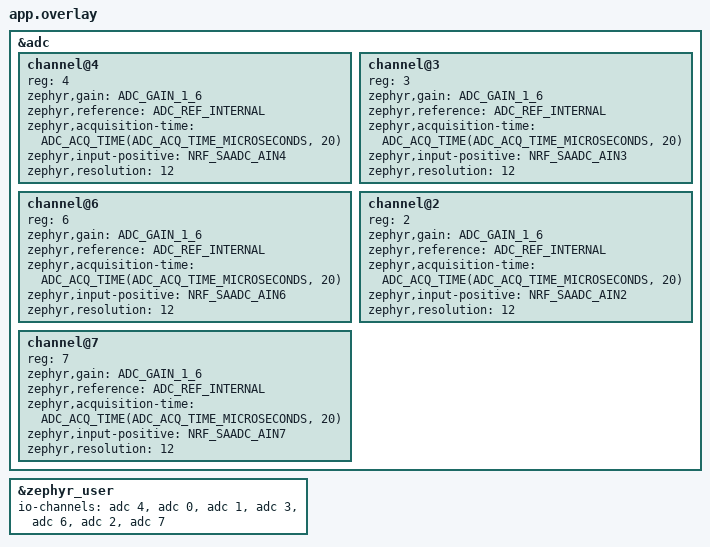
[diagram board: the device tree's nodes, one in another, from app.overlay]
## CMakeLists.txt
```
cmake_minimum_required(VERSION 3.20.0)
find_package(Zephyr REQUIRED HINTS $ENV{ZEPHYR_BASE})
project(wakes-sp1)

# Pulls in the samples' usbd bring-up helper (sample_usbd_init_device) and its
# CONFIG_SAMPLE_USBD_* options. Same approach as sp1-tape-looper. If this path is
# unavailable on your Zephyr, see docs/BUILD.md -> "USB console fallback".
include(${ZEPHYR_BASE}/samples/subsys/usb/common/common.cmake)

# ---- the engine list: generated from docs/PLAITS-ENGINES.md (M3b) ----
# The markdown table is the source of truth for engine order, LED patterns, enabled
# engines and centre detents. Edit it and rebuild; the build fails with a clear message
# if the table is malformed or a row's LED pattern does not match its position.
set(SP1_ENGINES_MD  ${CMAKE_CURRENT_SOURCE_DIR}/../docs/PLAITS-ENGINES.md)
set(SP1_ENGINES_GEN ${CMAKE_CURRENT_SOURCE_DIR}/../tools/gen_engines.py)
set(SP1_ENGINES_H   ${CMAKE_CURRENT_BINARY_DIR}/sp1_generated/sp1_engines_gen.h)
add_custom_command(
	OUTPUT  ${SP1_ENGINES_H}
	COMMAND ${Python3_EXECUTABLE} ${SP1_ENGINES_GEN} ${SP1_ENGINES_MD} ${SP1_ENGINES_H}
	DEPENDS ${SP1_ENGINES_MD} ${SP1_ENGINES_GEN}
	COMMENT "Generating the engine table from docs/PLAITS-ENGINES.md"
)
add_custom_target(sp1_engines_gen DEPENDS ${SP1_ENGINES_H})
add_dependencies(app sp1_engines_gen)
target_include_directories(app PRIVATE ${CMAKE_CURRENT_BINARY_DIR}/sp1_generated)

target_sources(app PRIVATE
	src/main.c
	src/sp1_led.c
	src/sp1_power.c
	src/sp1_batt.c
	src/sp1_standby.c
	src/sp1_console.c
	src/sp1_controls.c
	src/sp1_display.c
	src/sp1_calib.c
	src/sp1_audio.c
	src/sp1_meter.c
	src/sp1_playrow.c
	src/sp1_plaits_ui.c
)

# ---- M3: the Plaits voice (third_party/eurorack, vendored unmodified) ----
# Built as its own Zephyr library so it gets its OWN optimisation flags. The rest of
# the firmware is built -Os (CONFIG_SIZE_OPTIMIZATIONS); the DSP is the one place where
# cycles matter more than bytes, and the audio budget was measured assuming Plaits' own
# build: -O2 -funroll-loops, as in stmlib/makefile.inc for the Cortex-M4. Options added
# here come after the global ones on the command line, so this -O2 wins.
if(CONFIG_SP1_PLAITS)
	set(ER ${CMAKE_CURRENT_SOURCE_DIR}/../third_party/eurorack)

	zephyr_library_named(sp1_plaits)

	# ---- Plaits overrides: trims without modifying the vendored code ----
	# Two kinds, both leave third_party/ untouched:
	#
	# sp1_plaits_override(<file under third_party/eurorack> <exact upstream text>
	#                     <replacement>)                                   (M3e)
	#   Writes a copy of the file with ONE passage replaced into the build directory.
	#   A header copy shadows upstream's through the include path (searched first);
	#   a .cc copy is compiled INSTEAD of upstream's. The build stops if the upstream
	#   text is not found exactly once, so an upstream change can never silently
	#   disable a trim. At most one override per file.
	#
	# sp1_plaits_replace(<file under third_party/eurorack>)                (M3f)
	#   Our own rewrite of a whole file, kept at src/plaits_ovr/<same path> (attributed
	#   to upstream in its header and in NOTICE). Headers there shadow upstream's; a
	#   .cc there is compiled instead of upstream's.
	#
	# Each trim has a static_assert in sp1_synth.cc proving what was compiled.
	set(SP1_OVR ${CMAKE_CURRENT_BINARY_DIR}/plaits_overrides)
	set(SP1_REPL ${CMAKE_CURRENT_SOURCE_DIR}/src/plaits_ovr)
	set_property(GLOBAL PROPERTY SP1_PLAITS_SWAP "")
	function(sp1_plaits_swap rel ours)
		get_property(swaps GLOBAL PROPERTY SP1_PLAITS_SWAP)
		if("${rel}" IN_LIST swaps)
			message(FATAL_ERROR "Plaits override: ${rel} is overridden twice")
		endif()
		set_property(GLOBAL APPEND PROPERTY SP1_PLAITS_SWAP ${rel})
		set_property(GLOBAL PROPERTY SP1_PLAITS_SWAP_TO_${rel} ${ours})
	endfunction()
	function(sp1_plaits_override rel from to)
		set(src ${ER}/${rel})
		file(READ ${src} text)
		string(REPLACE "${from}" "" stripped "${text}")
		string(LENGTH "${text}" n0)
		string(LENGTH "${stripped}" n1)
		string(LENGTH "${from}" nf)
		math(EXPR count "(${n0} - ${n1}) / ${nf}")
		if(NOT count EQUAL 1)
			message(FATAL_ERROR
				"Plaits override: expected '${from}' exactly once in ${rel}, "
				"found ${count}. Upstream changed? Re-check the trim.")
		endif()
		if(EXISTS ${SP1_REPL}/${rel})
			message(FATAL_ERROR "Plaits override: ${rel} is also replaced in src/plaits_ovr")
		endif()
		string(REPLACE "${from}" "${to}" text "${text}")
		set(text "// GENERATED by firmware/CMakeLists.txt (sp1_plaits_override) from\n// third_party/eurorack/${rel}. Do not edit; see the override in CMakeLists.txt.\n${text}")
		# Write via configure_file so the copy's timestamp only changes when its
		# content does (no needless full Plaits rebuild on every reconfigure).
		file(WRITE ${SP1_OVR}/${rel}.tmp "${text}")
		configure_file(${SP1_OVR}/${rel}.tmp ${SP1_OVR}/${rel} COPYONLY)
		set_property(DIRECTORY APPEND PROPERTY CMAKE_CONFIGURE_DEPENDS ${src})
		if(rel MATCHES "\\.cc$")
			sp1_plaits_swap(${rel} ${SP1_OVR}/${rel})
		else()
			sp1_plaits_swap(${rel} "")
		endif()
	endfunction()
	function(sp1_plaits_replace rel)
		if(NOT EXISTS ${SP1_REPL}/${rel})
			message(FATAL_ERROR "Plaits replace: src/plaits_ovr/${rel} not found")
		endif()
		if(rel MATCHES "\\.cc$")
			sp1_plaits_swap(${rel} ${SP1_REPL}/${rel})
		else()
			sp1_plaits_swap(${rel} "")
		endif()
	endfunction()

	# M3e: String rings CONFIG_SP1_STRING_VOICES strings (upstream 3).
	sp1_plaits_override(plaits/dsp/engine/string_engine.h
		"const int kNumStrings = 3;"
		"const int kNumStrings = ${CONFIG_SP1_STRING_VOICES};")
	# M3f: Particle: CONFIG_SP1_PARTICLES particles (upstream 6). Plaits divides the
	# density by the count, so the event rate is unchanged.
	sp1_plaits_override(plaits/dsp/engine/particle_engine.h
		"const int kNumParticles = 6;"
		"const int kNumParticles = ${CONFIG_SP1_PARTICLES};")
	# M3f: Particle: skip the diffuser while MORPH >= centre, where Plaits mixes it in
	# at exactly 0 (diffusion = 0). Cleared when it comes back into use, so no stale
	# tail from the last time it ran is heard.
	sp1_plaits_override(plaits/dsp/engine/particle_engine.cc
		"  diffuser_.Process("
		"  // wakes-sp1 (M3f): the diffuser's mix amount is exactly 0 when diffusion is 0.\n  static bool sp1_diffusing = false;\n  if (diffusion > 0.0f && !sp1_diffusing) {\n    diffuser_.Reset();\n  }\n  sp1_diffusing = diffusion > 0.0f;\n  if (sp1_diffusing) diffuser_.Process(")
	# M3f: Modal: CONFIG_SP1_MODAL_MODES resonator modes (upstream 24). Resonator is
	# used by the modal engine only.
	sp1_plaits_override(plaits/dsp/physical_modelling/resonator.h
		"const int kMaxNumModes = 24;"
		"const int kMaxNumModes = ${CONFIG_SP1_MODAL_MODES};")
	# M3f: Additive: our rewrite of the partial summation (same 24 + 8 partials).
	sp1_plaits_replace(plaits/dsp/engine/additive_engine.h)
	sp1_plaits_replace(plaits/dsp/engine/additive_engine.cc)
	# M3g: String machine: the ensemble skips its taps while its amount is exactly 0
	# (TIMBRE on the centre detent); the divide-down oscillator (also used by Chords)
	# holds its gains per block. Both headers only.
	sp1_plaits_replace(plaits/dsp/fx/ensemble.h)
	sp1_plaits_replace(plaits/dsp/oscillator/string_synth_oscillator.h)
	# ---- M4a: a HARMONICS attenuverter (Adara) ----
	# Plaits' panel has attenuverters on FM, TIMBRE and MORPH but not on HARMONICS: its
	# HARMONICS CV is summed in raw, and -- the part that matters musically -- HARMONICS
	# is the one parameter the internal decay envelope can never reach, because that
	# routing is what an unpatched attenuverter means on the other three.
	#
	# These two overrides give HARMONICS the same treatment, which is a genuine addition
	# to Plaits rather than a re-binding. Together they add `harmonics_modulation_amount`
	# to Patch and `harmonics_patched` to Modulations, then run HARMONICS through the
	# same ApplyModulations() as the other three. The envelope amount is the plain
	# decay envelope, like TIMBRE's: the speech engine's `internal_envelope_amplitude`
	# is computed FROM p.harmonics, so using it here would be circular.
	#
	# ⚠️ Patch and Modulations are laid out by this header for EVERY Plaits file, so the
	# override must shadow upstream for all of them -- that is what SP1_OVR being first
	# on the include path does. sp1_synth.cc static_asserts that it took.
	# One passage, because a file may only be overridden once and the two new fields
	# live in two different structs.
	sp1_plaits_override(plaits/dsp/voice.h
		"  float morph_modulation_amount;

  int engine;
  float decay;
  float lpg_colour;
};

struct Modulations {
  float engine;
  float note;
  float frequency;
  float harmonics;
  float timbre;
  float morph;
  float trigger;
  float level;

  bool frequency_patched;"
		"  float morph_modulation_amount;
  // wakes-sp1 (M4a): HARMONICS gets an attenuverter of its own. Upstream has none.
  float harmonics_modulation_amount;

  int engine;
  float decay;
  float lpg_colour;

  // Proof to sp1_synth.cc's static_assert that this override was compiled.
  static const bool kSp1HarmonicsAttenuverter = true;
};

struct Modulations {
  float engine;
  float note;
  float frequency;
  float harmonics;
  float timbre;
  float morph;
  float trigger;
  float level;

  bool harmonics_patched;   // wakes-sp1 (M4a)
  bool frequency_patched;")
	sp1_plaits_override(plaits/dsp/voice.cc
		"  p.harmonics = patch.harmonics + modulations.harmonics;
  CONSTRAIN(p.harmonics, 0.0f, 1.0f);"
		"  // wakes-sp1 (M4a): HARMONICS through the same attenuverter + internal-envelope
  // path as TIMBRE and MORPH. Upstream is: p.harmonics = patch.harmonics +
  // modulations.harmonics, constrained to 0..1.
  p.harmonics = ApplyModulations(
      patch.harmonics,
      patch.harmonics_modulation_amount,
      modulations.harmonics_patched,
      modulations.harmonics,
      use_internal_envelope,
      decay_envelope_.value(),
      0.0f,
      0.0f,
      1.0f);")
	# ---- M4c: the X / Y voltage range becomes PER CHANNEL ----
	# Marbles' range is a per-GROUP setting and XYGenerator::Process writes it into each
	# channel's ScaleOffset itself, every block -- so anything we set per channel would be
	# overwritten. This makes that one switch ask us which range channel `i` should get.
	#
	# All the policy lives in sp1_marbles.cc (IntelligentRange); this override holds none,
	# and a non-INTELLIGENT group still gets exactly what upstream gave it. The local
	# extern declaration keeps it to a single replaced passage, which is the limit of one
	# override per file.
	sp1_plaits_override(marbles/random/x_y_generator.cc
		"    switch (settings.voltage_range) {"
		"    // wakes-sp1 (M4c): the range is per CHANNEL, not per group.
    // A block-scope extern declares the name in the innermost enclosing NAMESPACE, so
    // this is marbles::sp1_mrb_channel_range -- defined in firmware/src/sp1_marbles.cc.
    // (`extern \"C\"` is not allowed at block scope, hence C++ linkage.)
    extern int sp1_mrb_channel_range(int channel, int group_range);
    switch (static_cast<VoltageRange>(sp1_mrb_channel_range(
        static_cast<int>(i), static_cast<int>(settings.voltage_range)))) {")
	# M4: Marbles' t generator gets a setter for its master phase, so PLAY starts the
	# clock on a beat (sp1_marbles.cc). Nothing else in Marbles is changed.
	sp1_plaits_override(marbles/random/t_generator.h
		"  inline void set_model(TGeneratorModel model) {"
		"  // wakes-sp1 (M4): PLAY starts the clock on a beat.\n  inline void set_master_phase(float phase) {\n    master_phase_ = phase;\n  }\n\n  inline void set_model(TGeneratorModel model) {")

	set(PLAITS_SOURCES
		${ER}/plaits/dsp/voice.cc
		${ER}/plaits/resources.cc
		${ER}/stmlib/dsp/atan.cc
		${ER}/stmlib/dsp/units.cc
		${ER}/stmlib/utils/random.cc
	)
	file(GLOB PLAITS_ENGINE_SOURCES
		${ER}/plaits/dsp/engine/*.cc
		${ER}/plaits/dsp/engine2/*.cc
		${ER}/plaits/dsp/chords/*.cc
		${ER}/plaits/dsp/fm/*.cc
		${ER}/plaits/dsp/physical_modelling/*.cc
		${ER}/plaits/dsp/speech/*.cc
	)
	list(APPEND PLAITS_SOURCES ${PLAITS_ENGINE_SOURCES})
	# M4: Marbles' generators (third_party/eurorack/README.md), same library and flags.
	file(GLOB MARBLES_SOURCES
		${ER}/marbles/random/*.cc
		${ER}/marbles/ramp/*.cc
	)
	list(APPEND PLAITS_SOURCES ${MARBLES_SOURCES} ${ER}/marbles/resources.cc)
	get_property(swaps GLOBAL PROPERTY SP1_PLAITS_SWAP)
	foreach(rel ${swaps})
		get_property(ours GLOBAL PROPERTY SP1_PLAITS_SWAP_TO_${rel})
		if(ours)
			list(FIND PLAITS_SOURCES ${ER}/${rel} idx)
			if(idx EQUAL -1)
				message(FATAL_ERROR "Plaits override: ${rel} is not a Plaits source")
			endif()
			list(REMOVE_AT PLAITS_SOURCES ${idx})
			list(APPEND PLAITS_SOURCES ${ours})
		endif()
	endforeach()
	zephyr_library_sources(src/sp1_synth.cc src/sp1_marbles.cc ${PLAITS_SOURCES})

	# ⚠️ ORDER MATTERS: generated overrides, our replacements, the shim, then the
	# eurorack root. The shim's plaits/user_data.h shadows upstream's (which reads an
	# STM32 flash address that is a bus fault on the nRF52840). See
	# src/plaits_shim/plaits/user_data.h.
	zephyr_library_include_directories(
		${SP1_OVR}
		${SP1_REPL}
		src/plaits_shim
		${ER}
	)
	zephyr_library_compile_options(
		# GNU dialect, as upstream's own build (strict -std=c++14 from CONFIG_STD_CPP14
		# otherwise), plus _DEFAULT_SOURCE: Zephyr's feature macros hide M_PI in
		# picolibc's <math.h>, and stmlib and Plaits use it throughout.
		$<$<COMPILE_LANGUAGE:CXX>:-std=gnu++14>
		-D_DEFAULT_SOURCE
		-O2
		-funroll-loops
		-finline-functions-called-once
		-fno-move-loop-invariants
		# Upstream code, compiled as-is: silence what it was never written against.
		-Wno-unused-variable
		-Wno-unused-parameter
		-Wno-unused-local-typedefs
		-Wno-sign-compare
		-Wno-double-promotion
	)
	# A Zephyr library declared from the APPLICATION is not linked on its own.
	target_link_libraries(app PRIVATE sp1_plaits)
	target_sources(app PRIVATE src/sp1_marbles_ui.c)
	target_include_directories(app PRIVATE src)
endif()
```

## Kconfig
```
# wakes-sp1 application Kconfig.
#
# Pulls in the common USB sample options (CONFIG_SAMPLE_USBD_VID/PID/PRODUCT/...)
# consumed by the vendored sample_usbd_init helper, then the standard Zephyr tree.
source "samples/subsys/usb/common/Kconfig.sample_usbd"

menu "wakes-sp1"

config SP1_PLAITS
	bool "Plaits voice as the audio source (M3)"
	default y
	select CPP
	help
	  y: PLAY triggers the Plaits voice (2-op FM), faders are FREQUENCY /
	  TIMBRE / MORPH / HARMONICS, VOL+/- set the output level.
	  n: the M2 440 Hz test tone instead, with its PLAY / VOL controls, and
	  none of the Plaits code is compiled or linked.

	  This is the FALLBACK SWITCH. If the voice faults or overruns on hardware,
	  set CONFIG_SP1_PLAITS=n in prj.conf and rebuild: everything else in the
	  build (headphone mute, LEDs, power) stays exactly as it was.

config SP1_STRING_VOICES
	int "String engine: number of strings (Plaits kNumStrings)"
	range 1 3
	default 2
	depends on SP1_PLAITS
	help
	  How many strings Plaits' String engine rings at once. Upstream is 3.
	  Each TRIG plucks the next string round-robin, so this is how many
	  notes can overlap before the oldest one is re-plucked.

	  2 (default, M3e): every string costs the same, so 2 saves a third of
	  the engine -- 598.6 -> 427.3 instructions/sample in tools/plaits-bench,
	  about 90 % -> 65 % of the audio budget on the SP-1. At 3, String
	  measured 90 % average and 98.5 % peak: it played, with no headroom.

	  Applied at build time to a generated copy of string_engine.h; the
	  vendored file is not modified (see "Plaits overrides" in
	  firmware/CMakeLists.txt). Set it to 3 in prj.conf to A/B the original.

config SP1_PARTICLES
	int "Particle engine: number of particles (Plaits kNumParticles)"
	range 1 6
	default 2
	depends on SP1_PLAITS
	help
	  How many resonant "particles" Plaits' Particle engine runs. Upstream
	  is 6. Plaits divides the density by this count, so the rate of events
	  is the same; fewer means fewer pings ringing at different pitches at
	  once.

	  2 (default, M3h): at 3 (M3f) the SP-1 peaked at 83-100 %, all of it
	  below MORPH centre where the diffuser runs (Adara). Each particle is
	  ~43 instructions/sample. At 6 (upstream) it measured 86 % average /
	  97 % peak. The diffuser is skipped above MORPH centre in any case.

config SP1_MODAL_MODES
	int "Modal engine: number of resonator modes (Plaits kMaxNumModes)"
	range 4 24
	default 12
	depends on SP1_PLAITS
	help
	  Partials of Plaits' modal resonator. Upstream is 24. Must be a
	  multiple of 4 (the resonator renders modes in batches of 4; the build
	  checks). Fewer modes drop the highest partials: the body of a bell
	  stays, its shimmer goes.

	  12 (default, M3g): 8 measured 49 % average / 54 % peak on the SP-1
	  and sounded band-limited (Adara); each batch of 4 modes costs ~100
	  instructions/sample, ~16 %, so 12 is expected near 65 % / 70 %.
	  8 is the fallback. 16 would be ~80 % average -- over the target.

endmenu

source "Kconfig.zephyr"
```

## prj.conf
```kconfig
# wakes-sp1 M0 — the safety floor.
#
# Deliberately minimal. No USB, no console, no audio, no ADC. Every option
# here either keeps the device recoverable or is required to boot at all.
# Things are ADDED in later milestones, never removed to fix a build.

# ---- Recoverability ----
# The watchdog is the final backstop for a hang on a device with no reset pin.
CONFIG_WATCHDOG=y
# k_sys_fatal_error_handler() in main.c turns any fault into a cold reboot.
CONFIG_REBOOT=y

# ---- Fault containment ----
# HW_STACK_PROTECTION reprograms the MPU stack guard on every context switch.
# sp1-tape-looper measured that at ~1 % at the corner and turned it off in
# favour of the cheaper STACK_SENTINEL canary (which Kconfig excludes while
# MPU_STACK_GUARD is on). M0 has CPU to spare and no audio deadline yet, so
# keep the stronger guard here and revisit at M2 when the deadline is real.
CONFIG_HW_STACK_PROTECTION=y

# ---- USB CDC ACM console (M1c) ----
# Exists to make two things possible that are miserable blind: calibrating the
# battery divider, and building the button-ladder threshold tables in M1d.
#
# device_next rather than the legacy CONFIG_USB_DEVICE_STACK: legacy is smaller but
# deprecated, mass storage later would need device_next anyway, and this is the path
# sp1-tape-looper proved on this board and this Zephyr version.
CONFIG_CONSOLE=y
CONFIG_PRINTK=y
CONFIG_SERIAL=y
CONFIG_UART_CONSOLE=y
CONFIG_UART_LINE_CTRL=y
CONFIG_UART_INTERRUPT_DRIVEN=y

CONFIG_USB_DEVICE_STACK_NEXT=y
CONFIG_USBD_CDC_ACM_CLASS=y
# The app owns the single USBD context; do not let the CDC SYS_INIT build a second
# private one that would fight for the controller.
CONFIG_CDC_ACM_SERIAL_INITIALIZE_AT_BOOT=n
CONFIG_HWINFO=y
CONFIG_SAMPLE_USBD_PID=0x5211
CONFIG_SAMPLE_USBD_MANUFACTURER="worldwave"
CONFIG_SAMPLE_USBD_PRODUCT="wakes-sp1"
# iOS rejects accessories claiming more than 100 mA over the camera adapter, and we
# run from our own battery. Units of 2 mA.
CONFIG_SAMPLE_USBD_MAX_POWER=50

CONFIG_LOG=n
CONFIG_ASSERT=n

# The USB stack's init and printf need more main stack than the bare power build.
# 3 KB from M3 (was 2 KB): main now uses the FPU (fader smoothing), so every exception
# taken on its stack carries the extended FP frame, and it calls printk with more args.
CONFIG_MAIN_STACK_SIZE=3072

# ---- Clocking ----
# Matches what the bootloader leaves behind. Do not change without reading
# docs/SAFETY.md -- re-initialising bootloader-owned clocks is on the "do not"
# list for this board.
CONFIG_CLOCK_CONTROL=y
CONFIG_CLOCK_CONTROL_NRF_K32SRC_SYNTH=y


# ---- LED rows on hardware PWM (M1a) ----
# Hardware PWM costs no CPU (EasyDMA), unlike the software PWM sp1-tape-looper
# uses -- which needed a zero-latency IRQ to stop flicker and would compete with
# the audio deadline from M2 on. Do not replace this with a software PWM.
CONFIG_PWM=y
CONFIG_PWM_NRFX=y

# ---- Battery voltage (M1b) ----
# SAADC on AIN4. Only the battery channel for now; the faders join in M1c.
CONFIG_ADC=y

# ---- Output naming ----
# Renames build/zephyr/zephyr.{elf,bin,hex,map,...} to wakes-sp1.{elf,bin,hex,map,...}.
# The build/zephyr/ subdirectory itself is unaffected -- that name comes from the
# Zephyr CMake target, not this option.
CONFIG_KERNEL_BIN_NAME="wakes-sp1"

# ---- Audio output (M2) ----
# I2C to the two codecs (CS42L42 headphone at 0x48, TAS2505 speaker amp at 0x18),
# and the I2S stream as a CLOCK SLAVE on both clocks -- see sp1_audio.h for the
# topology. Same three options sp1-tape-looper proved on this board.
CONFIG_I2C=y
CONFIG_I2S=y
CONFIG_I2S_NRFX=y

# Floating-point unit. Nothing in M2 uses float -- the tone and the meter are
# integer-only on purpose -- but Plaits is float throughout from M3. Turning the FPU
# on HERE means M3 changes one thing (the synth), not two (the synth and the
# FP context-switch behaviour).
CONFIG_FPU=y
# Preserve FP registers across context switches. CONFIG_FPU alone is Zephyr's
# UNSHARED mode: FP state is not saved when threads switch. Plaits (float) will run in
# the audio thread, and any float in main, USB or an ISR would silently corrupt it --
# and with the hard-float ABI the compiler may use VFP registers for plain data moves
# too. Set now, with the FPU, so M3 does not inherit a latent corruption bug.
CONFIG_FPU_SHARING=y

# ---- M3: the Plaits voice ----
# The fallback switch: n = the M2 test tone, and no Plaits code is built at all.
CONFIG_SP1_PLAITS=y
# Plaits is C++ (no exceptions, no RTTI -- the Zephyr defaults) and needs <algorithm>
# and <cmath>, which the minimal C++ library does not provide.
CONFIG_CPP=y
CONFIG_STD_CPP14=y
CONFIG_GLIBCXX_LIBCPP=y
# ⚠️ The audio thread runs at K_PRIO_PREEMPT(0) and MUST outrank main, so main moves
# to 1. From M3 the audio work is ~half the CPU; at equal priority the ADC scan and
# every printk would compete with the audio deadline. See sp1_audio.h.
CONFIG_MAIN_THREAD_PRIORITY=1
```

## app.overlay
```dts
/*
 * wakes-sp1 application overlay.
 *
 * M1d adds the four faders, APPENDED after the battery so it keeps io-channel
 * index 0 and sp1_batt.c never has to be renumbered.
 *
 * `reg` is chosen to equal the AIN number for the faders, which makes the mapping
 * readable against the schematic. The io-channel INDEX is what C uses, and the two
 * are deliberately different things -- see sp1_controls.c.
 *
 * Gain 1/6 + ADC_REF_INTERNAL matches the ladder channels in the board DTS, and
 * that pairing is load-bearing: published millivolt threshold tables are only
 * valid under the ADC configuration they were measured in. sp1-midi uses gain 1/4
 * with VDD/4 -- never mix the two.
 */

#include <zephyr/dt-bindings/adc/adc.h>
#include <zephyr/dt-bindings/adc/nrf-saadc.h>

&adc {
	/* Battery voltage, P0.28 / AIN4, via an on-board divider of UNKNOWN ratio.
	 * See sp1_batt.h for how to calibrate it without opening the device. */
	channel@4 {
		reg = <4>;
		zephyr,gain = "ADC_GAIN_1_6";
		zephyr,reference = "ADC_REF_INTERNAL";
		zephyr,acquisition-time = <ADC_ACQ_TIME(ADC_ACQ_TIME_MICROSECONDS, 20)>;
		zephyr,input-positive = <NRF_SAADC_AIN4>;
		zephyr,resolution = <12>;
	};
};

&adc {
	/* Fader 1, P0.05 / AIN3 */
	channel@3 {
		reg = <3>;
		zephyr,gain = "ADC_GAIN_1_6";
		zephyr,reference = "ADC_REF_INTERNAL";
		zephyr,acquisition-time = <ADC_ACQ_TIME(ADC_ACQ_TIME_MICROSECONDS, 20)>;
		zephyr,input-positive = <NRF_SAADC_AIN3>;
		zephyr,resolution = <12>;
	};
	/* Fader 2, P0.30 / AIN6 */
	channel@6 {
		reg = <6>;
		zephyr,gain = "ADC_GAIN_1_6";
		zephyr,reference = "ADC_REF_INTERNAL";
		zephyr,acquisition-time = <ADC_ACQ_TIME(ADC_ACQ_TIME_MICROSECONDS, 20)>;
		zephyr,input-positive = <NRF_SAADC_AIN6>;
		zephyr,resolution = <12>;
	};
	/* Fader 3, P0.04 / AIN2 */
	channel@2 {
		reg = <2>;
		zephyr,gain = "ADC_GAIN_1_6";
		zephyr,reference = "ADC_REF_INTERNAL";
		zephyr,acquisition-time = <ADC_ACQ_TIME(ADC_ACQ_TIME_MICROSECONDS, 20)>;
		zephyr,input-positive = <NRF_SAADC_AIN2>;
		zephyr,resolution = <12>;
	};
	/* Fader 4, P0.31 / AIN7 */
	channel@7 {
		reg = <7>;
		zephyr,gain = "ADC_GAIN_1_6";
		zephyr,reference = "ADC_REF_INTERNAL";
		zephyr,acquisition-time = <ADC_ACQ_TIME(ADC_ACQ_TIME_MICROSECONDS, 20)>;
		zephyr,input-positive = <NRF_SAADC_AIN7>;
		zephyr,resolution = <12>;
	};
};

&zephyr_user {
	/* ORDER IS THE C-VISIBLE INDEX. Battery must stay index 0.
	 *   0 battery   1 ladder-tracks   2 ladder-vol
	 *   3 fader1    4 fader2          5 fader3       6 fader4
	 * See the IO_* defines in sp1_controls.c -- they must match this order. */
	io-channels = <&adc 4>,
		      <&adc 0>, <&adc 1>,
		      <&adc 3>, <&adc 6>, <&adc 2>, <&adc 7>;
};
```

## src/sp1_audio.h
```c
/*
 * wakes-sp1 — audio output: codecs, 48 kHz I2S, output level, headphone detect, and
 * the block loop that runs the synth voice (M3) or the fallback test tone.
 *
 * ---- clock topology (TE's own, and the only one proven on this board) ----
 * The 3.072 MHz oscillator (P0.13) drives the I2S bit clock. The CS42L42 headphone
 * codec is the FRAME master: it divides that clock by 64 to make a frame clock of
 * exactly 48 000 Hz. The nRF52840 I2S peripheral and the TAS2505 speaker amp are both
 * CLOCK SLAVES. sp1-tape-looper found the hard way that having the nRF master the
 * clocks instead (at ~47 619 Hz) crackled on the speaker and gave only noise on the
 * headphones.
 *
 * ---- bring-up order, copied exactly from the proven path. DO NOT "TIDY" IT ----
 *   1. release both codec resets, 20 ms
 *   2. oscillator ON, 5 ms          -> the bit clock now exists
 *   3. start the I2S stream         -> nRF waits as a slave; there is no frame yet
 *   4. configure the TAS2505        -> its PLL locks to the BIT clock, already live
 *   5. configure the CS42L42        -> it starts mastering the FRAME clock, and the
 *                                      stream the nRF queued in step 3 begins to flow
 * Step 3 before step 5 looks backwards and is not: the amp only needs the bit clock,
 * the nRF just waits for frames, and this is the order that works on hardware.
 *
 * ---- priority: audio OUTRANKS main (M3) ----
 * Audio runs at K_PRIO_PREEMPT(0); CONFIG_MAIN_THREAD_PRIORITY=1 in prj.conf puts the
 * main loop below it. In M2 both were 0 and time-sliced (TIMESLICE_PRIORITY=0, 20 ms
 * slices), which was fine for a sine at ~7 % of the CPU and not for Plaits at ~50 %:
 * a 430 us ADC scan or a printk stalled by the host could then sit in front of an
 * audio block. Now the audio thread takes the CPU whenever a block is due, and main
 * runs in the gaps.
 *
 * ---- and therefore the audio thread must NEVER spin ----
 * The main loop is what feeds the watchdog and runs power-off. A thread that spins
 * ABOVE it starves both.
 *
 * What an OVERRUN does (voice slower than real time) -- checked against the pinned
 * i2s_nrfx.c, and not what an earlier version of this comment claimed: the driver
 * misses a buffer ("next buffers not supplied"), the stream goes to I2S_STATE_ERROR,
 * i2s_write() then fails at once, and the write-failure path SLEEPS 2 ms per failure
 * and re-primes after 8. So main still gets time: the device stays up with broken,
 * stuttering audio and a slower control loop, and power-off keeps working. It does
 * NOT starve into a watchdog reset -- so when debugging an overrun in M4, look for
 * `fail`/`rst` climbing on the AUD line, not for a reboot. CONFIG_SP1_PLAITS=n builds
 * the known-good tone firmware.
 *
 * tape-looper's write-failure path does `free; continue` with no sleep, which spins if
 * writes fail instantly. Every path through this thread blocks or sleeps instead. See
 * sp1_audio.c.
 *
 * ---- start/stop are bounded, always ----
 * sp1_audio_stop() is on the POWER-OFF path (sp1_quiesce_peripherals calls it). It
 * never waits more than 50 ms for the thread, whatever state the thread is in, and
 * power-off proceeds regardless -- rule 5a: power-off does not depend on anything
 * else succeeding.
 */
#ifndef SP1_AUDIO_H
#define SP1_AUDIO_H

#include <stdint.h>
#include <stdbool.h>

/* Create the audio thread (it parks immediately) and enable the DWT cycle counter.
 * Once, at boot, after the power-on gate. Safe to call stop() before this. */
void sp1_audio_init(void);

/* Bring the audio path up: resets released, oscillator on, stream started, both
 * codecs configured. Call on every entry to ON -- the way into STANDBY powers all of
 * it down. Bounded: never blocks longer than ~1 s, feeds the watchdog while it waits.
 * Returns 0 on success, negative if the stream could not be started. */
int sp1_audio_start(void);

/* Stop the stream. On the power-off path: waits at most 50 ms for the thread, then
 * returns REGARDLESS. Safe to call when audio was never started. */
void sp1_audio_stop(void);

/* Halt the I2S peripheral at register level and disconnect its pins. ONLY on the way
 * to SYSTEM_OFF -- never STANDBY, because the driver applies its pinctrl once at boot
 * and would not restore the pins. See sp1_audio.c. */
void sp1_audio_halt_for_system_off(void);

/* Peak |sample| (0..32767) of everything produced since the last call, then reset.
 * For the meter. Lock-free: one atomic swap. */
uint32_t sp1_audio_take_peak(void);

/* ---- OUTPUT LEVEL (VOL+ / VOL-) ----
 * 3 dB steps, slewed in the audio path so a change never clicks. Step 0 = 0 dBFS; the
 * last step is mute. Every TWO steps is one meter band (6.02 dB). Applies to the synth
 * and to the fallback tone alike, and to speaker and headphones alike -- the speaker's
 * extra speaker trim is separate and fixed (SP1_SPK_ATTEN_HALF_DB in sp1_audio.c:
 * -9 dB in M3, -6 dB since M4a). */
#define SP1_LEVEL_STEPS     12      /* 0 .. 10 = 0 .. -30 dB, 11 = mute */
#if defined(CONFIG_SP1_PLAITS)
#define SP1_LEVEL_DEFAULT    2      /* -6 dBFS                                */
#else
#define SP1_LEVEL_DEFAULT    4      /* -12 dBFS for the test tone, as in M2   */
#endif

void sp1_audio_level_step(int delta);  /* +1 = quieter by 3 dB, -1 = louder */
int  sp1_audio_level_get(void);
int  sp1_audio_level_db_x10(void);     /* tenths of dBFS, -9990 = mute      */

/* ---- the fallback test tone (CONFIG_SP1_PLAITS=n only): 440 Hz, off at start ---- */
void sp1_audio_tone_set(bool on);
bool sp1_audio_tone_on(void);

/* ---- headphone detect -> speaker mute (M3) ----
 * Call from the main loop every tick while ON, after sp1_audio_start(). Polls the
 * CS42L42 jack sense every 40 ms, debounced, and powers the speaker down while a plug
 * is in. Returns -1 (nothing new), 0 (unplugged: speaker on), 1 (plugged: speaker
 * off), or 2 (detect failed repeatedly: disabled for this session, speaker ON). */
int sp1_audio_jack_poll(uint32_t elapsed_ms);
int sp1_audio_jack_state(void);        /* 1 in, 0 out, -1 unknown */

/* Block cost since the last call: worst and mean cycles per block. Read-and-clear. */
void sp1_audio_take_cycles(uint32_t *max, uint32_t *avg);

/* ---- diagnostics ---- */
struct sp1_audio_stats {
	uint32_t blocks;         /* blocks handed to I2S                         */
	uint32_t write_fails;    /* i2s_write errors                             */
	uint32_t restarts;       /* stream drop + re-prime after repeated fails  */
	uint32_t cyc_max;        /* worst cycles spent generating one block      */
	uint32_t cyc_budget;     /* cycles available per block                   */
	int      cfg_rc;         /* last i2s_configure() result                  */
	bool     running;
	bool     tas_ok;         /* every TAS2505 write ACKed                    */
	bool     hp_ok;          /* CS42L42 identified and configured            */
};
void sp1_audio_stats(struct sp1_audio_stats *out);

#endif /* SP1_AUDIO_H */
```

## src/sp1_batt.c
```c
/* wakes-sp1 — battery voltage and charge estimate. See sp1_batt.h. */
#include "sp1_batt.h"

#include <zephyr/kernel.h>
#include <zephyr/device.h>
#include <zephyr/devicetree.h>
#include <zephyr/drivers/adc.h>

/* The battery is io-channel index 0 on zephyr_user. Faders APPEND after it when
 * they arrive, so this index never has to move. */
#define BATT_IO_IDX 0

static const struct adc_dt_spec batt_spec =
	ADC_DT_SPEC_GET_BY_IDX(DT_PATH(zephyr_user), BATT_IO_IDX);

/* Full scale: gain 1/6 with the 0.6 V internal reference => 3.6 V across 12 bits.
 * These MUST match the channel properties in firmware/app.overlay. */
#define ADC_FULL_SCALE_MV  3600u
#define ADC_MAX_COUNTS     4095u

/* SP1_BATT_DIVIDER_MILLI lives in sp1_batt.h so the console can report what we
 * are currently assuming alongside what it measured. A /2 divider is the likely
 * design: it puts a 4.20 V cell at 2.10 V, well inside the 3.6 V window. */

static uint16_t raw_last;
static uint16_t mv_last;
static bool     have_sample;
static bool     adc_ok;

/* Smoothed millivolts for display. Raw readings scatter +/-8 counts (~15 mV at the
 * cell), which made the computed level jitter between 247 and 255 -- visible as the
 * top LED of the charge bar wobbling. Hardware oversampling below takes most of it
 * out; this takes the rest. */
static uint32_t mv_smooth_q4;      /* millivolts, Q4 fixed point */
#define SMOOTH_SHIFT 3             /* first-order IIR, ~8-sample time constant */

int sp1_batt_init(void)
{
	if (!adc_is_ready_dt(&batt_spec)) {
		return -1;
	}
	if (adc_channel_setup_dt(&batt_spec) < 0) {
		return -1;
	}
	adc_ok = true;
	return 0;
}

void sp1_batt_sample(void)
{
	if (!adc_ok) {
		return;
	}

	int16_t buf = 0;
	struct adc_sequence seq = {
		.buffer      = &buf,
		.buffer_size = sizeof(buf),
	};
	if (adc_sequence_init_dt(&batt_spec, &seq) < 0) {
		return;
	}
	/* Hardware oversampling: the SAADC averages 2^n conversions for us, which is
	 * free compared with doing it in software.
	 *
	 * ⚠️ M1d NOTE: nrfx cannot oversample a sequence containing MORE THAN ONE
	 * channel. When the faders arrive, keep the battery in its own single-channel
	 * sequence rather than folding it into a scan, or this silently stops working. */
	seq.oversampling = 4;      /* 2^4 = 16 conversions averaged */
	if (adc_read(batt_spec.dev, &seq) < 0) {
		return;
	}

	if (buf < 0) {
		buf = 0;          /* single-ended; a negative code is noise */
	}
	raw_last = (uint16_t)buf;
	/* raw -> mV at the pin -> mV at the cell. Ordered to keep the intermediate
	 * inside uint32: raw (<=4095) * 3600 is ~14.7e6, fine. */
	const uint32_t pin_mv = ((uint32_t)raw_last * ADC_FULL_SCALE_MV)
				/ ADC_MAX_COUNTS;
	const uint32_t mv_now = (pin_mv * SP1_BATT_DIVIDER_MILLI) / 1000u;

	if (!have_sample) {
		mv_smooth_q4 = mv_now << 4;      /* seed, do not ramp from zero */
	} else {
		mv_smooth_q4 += ((int32_t)(mv_now << 4) - (int32_t)mv_smooth_q4)
				>> SMOOTH_SHIFT;
	}
	mv_last = (uint16_t)(mv_smooth_q4 >> 4);
	have_sample = true;
}

uint16_t sp1_batt_raw(void) { return raw_last; }
uint16_t sp1_batt_mv(void)  { return mv_last; }
bool sp1_batt_valid(void)   { return have_sample; }

/* Resting Li-ion voltage -> state of charge. Voltage is a poor proxy for charge
 * on its own -- the curve is flat through the middle -- so this is a coarse
 * lookup, which is all a four-LED bar can express anyway. */
struct soc_point { uint16_t mv; uint8_t pct; };
static const struct soc_point soc_curve[] = {
	{ 3300,   0 }, { 3500,   5 }, { 3620,  10 }, { 3700,  20 },
	{ 3740,  30 }, { 3780,  40 }, { 3820,  50 }, { 3880,  60 },
	{ 3950,  70 }, { 4000,  80 }, { 4100,  90 }, { 4200, 100 },
};
#define SOC_POINTS (sizeof(soc_curve) / sizeof(soc_curve[0]))

uint8_t sp1_batt_level(void)
{
	if (!have_sample) {
		return 128u;    /* neutral midpoint rather than a scary empty bar */
	}
	const uint16_t mv = mv_last;

	if (mv <= soc_curve[0].mv) {
		return 0u;
	}
	if (mv >= soc_curve[SOC_POINTS - 1].mv) {
		return 255u;
	}
	for (size_t i = 1; i < SOC_POINTS; i++) {
		if (mv < soc_curve[i].mv) {
			const struct soc_point *a = &soc_curve[i - 1];
			const struct soc_point *b = &soc_curve[i];
			const uint32_t span_mv  = (uint32_t)(b->mv - a->mv);
			const uint32_t span_pct = (uint32_t)(b->pct - a->pct);
			const uint32_t pct = (uint32_t)a->pct +
				((uint32_t)(mv - a->mv) * span_pct) / span_mv;
			return (uint8_t)((pct * 255u) / 100u);
		}
	}
	return 255u;
}
```

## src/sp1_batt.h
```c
/*
 * wakes-sp1 — battery voltage and charge estimate.
 *
 * ⚠️ THE DIVIDER RATIO IS PROVISIONAL. The SP-1-dev wiki says only that the cell
 * is "directly tied to PIN_BATT_LEVEL over a voltage divider" and does not give
 * the ratio. SP1_BATT_DIVIDER_MILLI below is an assumption, so every percentage
 * this module reports carries an unknown scale error until it is calibrated.
 *
 * Calibrating it needs no multimeter and no disassembly. The BQ24232 terminates
 * at 4.20 V and says so: nCHG goes high while nPGOOD stays low. At that moment
 * the cell is at 4.20 V by definition, so
 *
 *     divider = 4.20 / (raw / 4095 * 3.6)
 *
 * The console (M1c) prints that line for you: plug in with a full battery and read
 * the CALIBRATION line. sp1_batt_raw() is what it reports.
 */
#ifndef SP1_BATT_H
#define SP1_BATT_H

#include <stdint.h>
#include <stdbool.h>

/* Cell-to-AIN4 divider, x1000 (2000 == a /2 divider).
 *
 * MEASURED 2026-09-20 from 28 console samples with the charger in CV taper, where
 * the BQ24232 holds the terminal at its 4.20 V target:
 *
 *     mean raw 2382.9  ->  V_pin 2094.9 mV  ->  divider 2.0049
 *     per-sample spread 2375..2392 (17 counts) = +/-15 mV at the cell
 *
 * So the /2 guess was right to within the measurement noise -- the correction is
 * 10.5 mV against +/-15 mV of scatter. 2005 is kept because it makes a full cell
 * read as full rather than ~98 %, but do NOT trust the third digit. A reading taken
 * at true termination (chg=0) would confirm it; the difference will be invisible. */
#define SP1_BATT_DIVIDER_MILLI  2005u

/* Bring up the SAADC channel for AIN4. Returns 0 on success; on failure the
 * readers below report a safe midpoint rather than faulting. */
int sp1_batt_init(void);

/* Sample the battery. Call at most every few hundred ms -- it blocks for the
 * conversion. */
void sp1_batt_sample(void);

/* Last raw 12-bit SAADC reading. For calibration. */
uint16_t sp1_batt_raw(void);

/* Last reading in millivolts at the CELL, i.e. after the divider is applied.
 * Carries the provisional-divider error. */
uint16_t sp1_batt_mv(void);

/* Estimated charge, 0-255 for direct use as a bar level.
 *
 * ⚠️ Reads HIGH while charging: the charger holds the terminal voltage above the
 * cell's resting voltage, so a charging battery always looks fuller than it is.
 * nCHG going high is the trustworthy "complete" signal, not this number. */
uint8_t sp1_batt_level(void);

/* True once the reading is meaningful (at least one sample taken). */
bool sp1_batt_valid(void);

#endif /* SP1_BATT_H */
```

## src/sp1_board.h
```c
/*
 * wakes-sp1 — SP-1 hardware pin map.
 *
 * Pin numbers from timknapen/SP-1-dev src/stemplayer_pins.h (MIT).
 * The LED port/pin pairs are the map chattock/sp1-tape-looper (MIT) marks as
 * hardware-verified; note that TimK's header lists the playback LEDs in a
 * different order. Trust the verified map, not the header ordering.
 */
#ifndef SP1_BOARD_H
#define SP1_BOARD_H

#include <zephyr/kernel.h>
#include <soc.h>

/* ---- Function button "••" : direct GPIO, pull-up, active low ---- */
#define SP1_FNC_PORT        NRF_P0
#define SP1_FNC_PIN         27u

/* ---- Button-ladder common rail (powers both resistor ladders) ---- */
#define SP1_BTN_COM_PORT    NRF_P1
#define SP1_BTN_COM_PIN     10u

/* ---- BQ24232 battery charger ----
 * The charger IC runs the CC/CV profile, termination, safety timer and thermal
 * regulation autonomously. Firmware CANNOT set the charge current: ISET is a
 * current-MONITORING output (an ADC input here), not a control. The part is
 * hardware-configured for 500 mA max USB draw. Our whole job is: hold nCE low
 * to enable charging, and read the two status pins. */
#define SP1_BQ_PORT         NRF_P0
#define SP1_BQ_NCE_PIN      21u   /* out, ACTIVE LOW: drive low = charging on   */
#define SP1_BQ_NCHG_PIN     22u   /* in, open-drain, LOW = charging now         */
#define SP1_BQ_NPGOOD_PIN   24u   /* in, open-drain, LOW = USB power present    */
/* ISET P1.00 and BATT_LEVEL P0.28/AIN4 are ADC inputs; used from M1 on. */

/* ---- Reset / enable lines for the chips around the nRF ---- */
#define SP1_TAS_RST_PORT    NRF_P0   /* TAS2505 speaker amp, active low  */
#define SP1_TAS_RST_PIN     9u
#define SP1_CS42_RST_PORT   NRF_P0   /* CS42L42 headphone codec, act low */
#define SP1_CS42_RST_PIN    15u
#define SP1_OSC_EN_PORT     NRF_P0   /* 3.072 MHz audio osc, active high  */
#define SP1_OSC_EN_PIN      13u
#define SP1_EMMC_VCCQ_PORT  NRF_P0   /* eMMC I/O rail, active high        */
#define SP1_EMMC_VCCQ_PIN   14u
#define SP1_BT_RST_PORT     NRF_P0   /* CYBT module, active low           */
#define SP1_BT_RST_PIN      10u

/* ---- LEDs: owned by PWM, NOT by GPIO ----
 * Both rows are driven by hardware PWM (PWM2 = track row, PWM3 = play row) and
 * their pins are claimed by pinctrl. DO NOT write these pins as GPIO -- it
 * fights the PWM peripheral and produces flicker or a stuck LED. Use the
 * sp1_led.h API.
 *
 * Recorded here only because the pinctrl CHANNEL ORDER in
 * boards/teenageengineering/stem_player/stem_player-pinctrl.dtsi must match the
 * LED indices, and changing one without the other scrambles the display:
 *
 *   track row (PWM2), the "model row" above T1-T4:
 *     ch0 = P0.29   ch1 = P0.26   ch2 = P1.15   ch3 = P1.14
 *   play row (PWM3), the side row / VU meter:
 *     ch0 = P1.13   ch1 = P0.00   ch2 = P1.12   ch3 = P0.01
 *
 * This is the order sp1-tape-looper marks as hardware-verified. TimK's
 * stemplayer_pins.h lists the play LEDs differently -- trust this one. */

#endif /* SP1_BOARD_H */
```

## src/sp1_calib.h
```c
/*
 * wakes-sp1 — guided, SELF-LABELLING ladder calibration.
 *
 * ---- why this exists ----
 * The M1d-a raw capture worked: it produced clean, tight plateaus (spreads of ~6
 * counts out of 4095). What it could not produce was *labels*. A 73-second firehose
 * of numbers tells you that eleven distinct levels exist on the tracks ladder; it
 * cannot tell you which one was T2 and which was T1+T4, because that lives in the
 * tester's memory and has to survive being written down in the right order.
 *
 * On the first attempt it did not survive: the capture contains eight presses where
 * the procedure called for nine, several repeats, and a part-5 sag measurement that
 * was performed with every fader parked at zero, where sag is invisible by
 * construction. None of that is a testing failure — it is a procedure that asked a
 * human to be a reliable data logger while also operating the device.
 *
 * So the firmware labels the data itself. It names one target at a time, waits for a
 * stable plateau, records it against that name, and waits for release before moving
 * on. The operator's whole job becomes "press what it just asked for". At the end it
 * prints a paste-ready C table.
 *
 * ---- properties that matter ----
 *   - TICK-DRIVEN AND NON-BLOCKING. Never spins, never waits on the console. The
 *     watchdog keeps being fed by the main loop and "••" keeps working throughout,
 *     which on a device with no reset pin is not negotiable.
 *   - A step that is not answered within SP1_CALIB_STEP_TIMEOUT_MS is marked SKIPPED
 *     and the run moves on. That is the escape hatch: wait it out. There is no
 *     "cancel" chord, because every chord is a control this is trying to measure.
 *   - It prints the live ladder value about once a second while waiting, so a step
 *     that never triggers still leaves evidence of what the ADC was seeing.
 */
#ifndef SP1_CALIB_H
#define SP1_CALIB_H

#include <stdint.h>
#include <stdbool.h>

/* ---- re-running calibration once the tables are populated ----
 * Set this to 1 and rebuild. It is a header constant and NOT a build-system flag
 * because `west build -- -DSP1_FORCE_CALIB=1` does not do what it looks like: after
 * the `--`, -D defines a CMAKE variable, not a C preprocessor macro, so the #if
 * never fires and calibration silently does not run. That cost a flash cycle on
 * 2026-09-19. One line to edit here, no build-system subtleties. */
#define SP1_FORCE_CALIB 0   /* ⚠️ back to 0 after every re-run: at 1 the wizard
                             * restarts on EVERY entry to ON, which is exactly what
                             * happened at the end of the 2026-09-20 session */

/* Begin a run from the top. Safe to call again to restart. */
void sp1_calib_start(void);

/* Advance one control tick. No-op when not running. */
void sp1_calib_tick(uint32_t elapsed_ms);

/* True while a run is in progress. */
bool sp1_calib_running(void);

#endif /* SP1_CALIB_H */
```

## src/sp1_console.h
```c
/*
 * wakes-sp1 — USB CDC ACM console.
 *
 * Exists mainly to make two things possible that are miserable blind:
 *   1. calibrating the battery divider (see sp1_batt.h)
 *   2. building the button-ladder threshold tables in M1d, which means watching
 *      raw ADC values while pressing buttons and combinations
 *
 * ⚠️ NEVER call into this from the audio path once M2 lands. printk over CDC ACM
 * can block for milliseconds when a host is attached and the endpoint is busy.
 * The audio budget is 1333 cycles per sample. Status printing belongs in the
 * ~8 ms control loop and nowhere else.
 *
 * ⚠️ It must NOT wait for a host. Blocking on DTR would mean the device does not
 * boot unplugged, which is most of the time.
 */
#ifndef SP1_CONSOLE_H
#define SP1_CONSOLE_H

#include <stdbool.h>
#include <stdint.h>

/* Bring up USB and the CDC ACM console. Returns 0 on success. Never blocks
 * waiting for a host; if USB fails the rest of the firmware carries on silently. */
int sp1_console_init(void);

/* Record and print the boot banner: build identity, reset reason, and the fault
 * breadcrumb from the previous boot if there was one. Call once, after init.
 *
 * The values are RETAINED, and re-printed by sp1_console_poll() every time a
 * terminal attaches (DTR rising). Printing once at boot loses it: USB enumeration
 * takes hundreds of milliseconds and the host may not open the port for seconds
 * after that. Confirmed on hardware 2026-09-20 -- a capture showed nine buffered
 * status lines flushed on attach but no banner. Waiting for a host is not an
 * option; the device has to boot unplugged. */
void sp1_console_banner(uint32_t resetreas, bool had_fault,
			uint32_t fault_reason, uint32_t fault_pc);

/* Set how often status lines are emitted, in milliseconds.
 * SP1_CONSOLE_PERIOD_OFF (0) disables them; the banner and the calibration line
 * still appear. Each loop sets this on entry, because ON and STANDBY want very
 * different cadences -- see sp1_ui_timing.h.
 *
 * ⚠️ M2: set this to OFF once audio is live unless actively debugging. printk over
 * CDC ACM can block for an unbounded time if the host stalls, which is a dropout
 * rather than a percentage of CPU. */
void sp1_console_set_status_period(uint32_t ms);

/* Call between the lines of any multi-line dump. CDC ACM drops characters rather
 * than blocking once its ring buffer is full, so a forty-line burst inside one
 * control tick loses data mid-line -- confirmed on hardware, see sp1_console.c.
 * Control loop only; never from the audio path. */
void sp1_console_pace(void);

/* Raw control capture (M1d-a). When on, every channel is dumped at ~20 Hz so the
 * ladder threshold tables can be MEASURED rather than guessed. Off by default;
 * this is a deliberate firehose and it must not be left on with audio running. */
void sp1_console_set_raw_capture(bool on);
bool sp1_console_raw_capture(void);

/* Call once per control tick from every loop that runs (ON and STANDBY). Emits a
 * status line about once a second, and the calibration line whenever the charger
 * reports complete. Cheap when there is nothing to say. */
void sp1_console_poll(uint32_t elapsed_ms, const char *state);

#endif /* SP1_CONSOLE_H */
```
